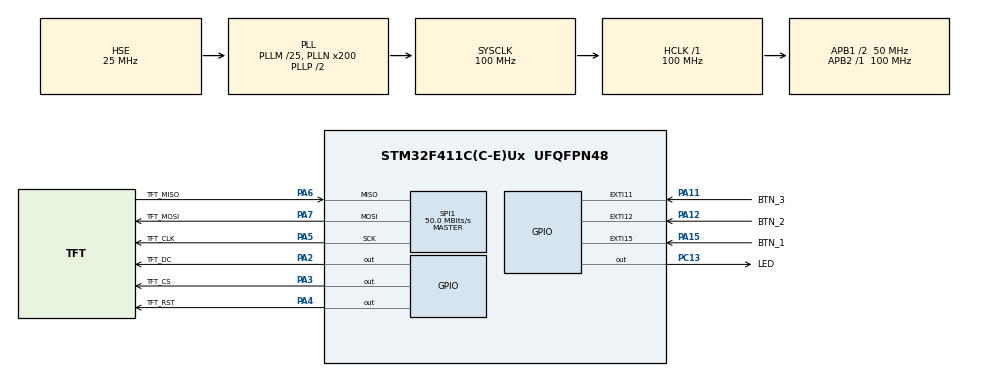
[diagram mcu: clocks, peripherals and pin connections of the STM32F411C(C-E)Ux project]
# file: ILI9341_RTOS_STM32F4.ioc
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Dma.Request0=SPI1_TX
Dma.SPI1_TX.0.Direction=DMA_MEMORY_TO_PERIPH
Dma.SPI1_TX.0.FIFOMode=DMA_FIFOMODE_DISABLE
Dma.SPI1_TX.0.Instance=DMA2_Stream2
Dma.SPI1_TX.0.MemDataAlignment=DMA_MDATAALIGN_BYTE
Dma.SPI1_TX.0.MemInc=DMA_MINC_ENABLE
Dma.SPI1_TX.0.Mode=DMA_NORMAL
Dma.SPI1_TX.0.PeriphDataAlignment=DMA_PDATAALIGN_BYTE
Dma.SPI1_TX.0.PeriphInc=DMA_PINC_DISABLE
Dma.SPI1_TX.0.Priority=DMA_PRIORITY_MEDIUM
FREERTOS.Tasks01=defaultTask,24,128,StartDefaultTask,Default,NULL,Dynamic,NULL,NULL
FREERTOS.configUSE_NEWLIB_REENTRANT=1
Mcu.Family=STM32F4
Mcu.Name=STM32F411C(C-E)Ux
Mcu.Package=UFQFPN48
NVIC.DMA2_Stream2_IRQn=true\:5\:0\:false\:false\:true\:true\:false\:true\:true
NVIC.EXTI15_10_IRQn=true\:5\:0\:false\:false\:true\:true\:true\:true\:true
NVIC.PriorityGroup=NVIC_PRIORITYGROUP_4
NVIC.TIM1_UP_TIM10_IRQn=true\:15\:0\:false\:false\:true\:false\:false\:true\:true
NVIC.TimeBase=TIM1_UP_TIM10_IRQn
NVIC.TimeBaseIP=TIM1
PA11.GPIO_Label=BTN_3
PA11.GPIO_ModeDefaultEXTI=GPIO_MODE_IT_FALLING
PA11.GPIO_PuPd=GPIO_PULLUP
PA11.Signal=GPXTI11
PA12.GPIO_Label=BTN_2
PA12.GPIO_ModeDefaultEXTI=GPIO_MODE_IT_FALLING
PA12.GPIO_PuPd=GPIO_PULLUP
PA12.Signal=GPXTI12
PA15.GPIO_Label=BTN_1
PA15.GPIO_ModeDefaultEXTI=GPIO_MODE_IT_FALLING
PA15.GPIO_PuPd=GPIO_PULLUP
PA15.Signal=GPXTI15
PA2.GPIO_Label=TFT_DC
PA2.GPIO_Speed=GPIO_SPEED_FREQ_VERY_HIGH
PA2.PinState=GPIO_PIN_SET
PA2.Signal=GPIO_Output
PA3.GPIO_Label=TFT_CS
PA3.GPIO_Speed=GPIO_SPEED_FREQ_VERY_HIGH
PA3.PinState=GPIO_PIN_SET
PA3.Signal=GPIO_Output
PA4.GPIO_Label=TFT_RST
PA4.GPIO_Speed=GPIO_SPEED_FREQ_VERY_HIGH
PA4.PinState=GPIO_PIN_SET
PA4.Signal=GPIO_Output
PA5.GPIO_Label=TFT_CLK
PA5.Mode=Full_Duplex_Master
PA5.Signal=SPI1_SCK
PA6.GPIO_Label=TFT_MISO
PA6.Mode=Full_Duplex_Master
PA6.Signal=SPI1_MISO
PA7.GPIO_Label=TFT_MOSI
PA7.Mode=Full_Duplex_Master
PA7.Signal=SPI1_MOSI
PC13-ANTI_TAMP.GPIO_Label=LED
PC13-ANTI_TAMP.GPIO_PuPd=GPIO_NOPULL
PC13-ANTI_TAMP.PinState=GPIO_PIN_SET
PC13-ANTI_TAMP.Signal=GPIO_Output
PH0\ -\ OSC_IN.Mode=HSE-External-Oscillator
PH0\ -\ OSC_IN.Signal=RCC_OSC_IN
PH1\ -\ OSC_OUT.Mode=HSE-External-Oscillator
PH1\ -\ OSC_OUT.Signal=RCC_OSC_OUT
ProjectManager.HeapSize=0x200
ProjectManager.StackSize=0x400
ProjectManager.TargetToolchain=STM32CubeIDE
RCC.48MHZClocksFreq_Value=50000000
RCC.AHBFreq_Value=100000000
RCC.APB1CLKDivider=RCC_HCLK_DIV2
RCC.APB1Freq_Value=50000000
RCC.APB1TimFreq_Value=100000000
RCC.APB2Freq_Value=100000000
RCC.APB2TimFreq_Value=100000000
RCC.CortexFreq_Value=100000000
RCC.HCLKFreq_Value=100000000
RCC.HSE_VALUE=25000000
RCC.HSI_VALUE=16000000
RCC.LSE_VALUE=32768
RCC.PLLM=25
RCC.PLLN=200
RCC.PLLSourceVirtual=RCC_PLLSOURCE_HSE
RCC.SYSCLKFreq_VALUE=100000000
RCC.SYSCLKSource=RCC_SYSCLKSOURCE_PLLCLK
RCC.VCOOutputFreq_Value=200000000
SPI1.CalculateBaudRate=50.0 MBits/s
SPI1.Direction=SPI_DIRECTION_2LINES
SPI1.Mode=SPI_MODE_MASTER
SPI1.VirtualType=VM_MASTER
VP_FREERTOS_VS_CMSIS_V2.Mode=CMSIS_V2
VP_SYS_VS_tim1.Mode=TIM1
board=custom

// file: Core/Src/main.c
/* USER CODE BEGIN Header */
/**
  ******************************************************************************
  * @file           : main.c
  * @brief          : Main program body
  ******************************************************************************
  * @attention
  *
  * Copyright (c) 2022 STMicroelectronics.
  * All rights reserved.
  *
  * This software is licensed under terms that can be found in the LICENSE file
  * in the root directory of this software component.
  * If no LICENSE file comes with this software, it is provided AS-IS.
  *
  ******************************************************************************
  */
/* USER CODE END Header */
#include "main.h"
#include "cmsis_os.h"

/* USER CODE BEGIN Includes */
#include "usercode.h"
/* USER CODE END Includes */

 SPI_HandleTypeDef hspi1;
DMA_HandleTypeDef hdma_spi1_tx;

/* Definitions for defaultTask */
osThreadId_t defaultTaskHandle;
const osThreadAttr_t defaultTask_attributes = {
  .name = "defaultTask",
  .stack_size = 128 * 4,
  .priority = (osPriority_t) osPriorityNormal,
};

void SystemClock_Config(void);
static void MX_GPIO_Init(void);
static void MX_DMA_Init(void);
static void MX_SPI1_Init(void);
void StartDefaultTask(void *argument);

int main(void)
{

  /* MCU Configuration--------------------------------------------------------*/

  /* Reset of all peripherals, Initializes the Flash interface and the Systick. */
  HAL_Init();

  /* Configure the system clock */
  SystemClock_Config();

  /* Initialize all configured peripherals */
  MX_GPIO_Init();
  MX_DMA_Init();
  MX_SPI1_Init();
  /* USER CODE BEGIN 2 */
  inicializar();
  userRTOS();
  /* USER CODE END 2 */

  /* Init scheduler */
  osKernelInitialize();

  /* Create the thread(s) */
  /* creation of defaultTask */
  defaultTaskHandle = osThreadNew(StartDefaultTask, NULL, &defaultTask_attributes);

  /* Start scheduler */
  osKernelStart();

  /* We should never get here as control is now taken by the scheduler */
  /* Infinite loop */
  while (1)
  {

  }
}

void SystemClock_Config(void)
{
  RCC_OscInitTypeDef RCC_OscInitStruct = {0};
  RCC_ClkInitTypeDef RCC_ClkInitStruct = {0};

  /** Configure the main internal regulator output voltage
  */
  __HAL_RCC_PWR_CLK_ENABLE();
  __HAL_PWR_VOLTAGESCALING_CONFIG(PWR_REGULATOR_VOLTAGE_SCALE1);

  /** Initializes the RCC Oscillators according to the specified parameters
  * in the RCC_OscInitTypeDef structure.
  */
  RCC_OscInitStruct.OscillatorType = RCC_OSCILLATORTYPE_HSE;
  RCC_OscInitStruct.HSEState = RCC_HSE_ON;
  RCC_OscInitStruct.PLL.PLLState = RCC_PLL_ON;
  RCC_OscInitStruct.PLL.PLLSource = RCC_PLLSOURCE_HSE;
  RCC_OscInitStruct.PLL.PLLM = 25;
  RCC_OscInitStruct.PLL.PLLN = 200;
  RCC_OscInitStruct.PLL.PLLP = RCC_PLLP_DIV2;
  RCC_OscInitStruct.PLL.PLLQ = 4;
  if (HAL_RCC_OscConfig(&RCC_OscInitStruct) != HAL_OK)
  {
    Error_Handler();
  }

  /** Initializes the CPU, AHB and APB buses clocks
  */
  RCC_ClkInitStruct.ClockType = RCC_CLOCKTYPE_HCLK|RCC_CLOCKTYPE_SYSCLK
                              |RCC_CLOCKTYPE_PCLK1|RCC_CLOCKTYPE_PCLK2;
  RCC_ClkInitStruct.SYSCLKSource = RCC_SYSCLKSOURCE_PLLCLK;
  RCC_ClkInitStruct.AHBCLKDivider = RCC_SYSCLK_DIV1;
  RCC_ClkInitStruct.APB1CLKDivider = RCC_HCLK_DIV2;
  RCC_ClkInitStruct.APB2CLKDivider = RCC_HCLK_DIV1;

  if (HAL_RCC_ClockConfig(&RCC_ClkInitStruct, FLASH_LATENCY_3) != HAL_OK)
  {
    Error_Handler();
  }
}

static void MX_SPI1_Init(void)
{

  /* SPI1 parameter configuration*/
  hspi1.Instance = SPI1;
  hspi1.Init.Mode = SPI_MODE_MASTER;
  hspi1.Init.Direction = SPI_DIRECTION_2LINES;
  hspi1.Init.DataSize = SPI_DATASIZE_8BIT;
  hspi1.Init.CLKPolarity = SPI_POLARITY_LOW;
  hspi1.Init.CLKPhase = SPI_PHASE_1EDGE;
  hspi1.Init.NSS = SPI_NSS_SOFT;
  hspi1.Init.BaudRatePrescaler = SPI_BAUDRATEPRESCALER_2;
  hspi1.Init.FirstBit = SPI_FIRSTBIT_MSB;
  hspi1.Init.TIMode = SPI_TIMODE_DISABLE;
  hspi1.Init.CRCCalculation = SPI_CRCCALCULATION_DISABLE;
  hspi1.Init.CRCPolynomial = 10;
  if (HAL_SPI_Init(&hspi1) != HAL_OK)
  {
    Error_Handler();
  }

}

static void MX_DMA_Init(void)
{

  /* DMA controller clock enable */
  __HAL_RCC_DMA2_CLK_ENABLE();

  /* DMA interrupt init */
  /* DMA2_Stream2_IRQn interrupt configuration */
  HAL_NVIC_SetPriority(DMA2_Stream2_IRQn, 5, 0);
  HAL_NVIC_EnableIRQ(DMA2_Stream2_IRQn);

}

static void MX_GPIO_Init(void)
{
  GPIO_InitTypeDef GPIO_InitStruct = {0};

  /* GPIO Ports Clock Enable */
  __HAL_RCC_GPIOC_CLK_ENABLE();
  __HAL_RCC_GPIOH_CLK_ENABLE();
  __HAL_RCC_GPIOA_CLK_ENABLE();

  /*Configure GPIO pin Output Level */
  HAL_GPIO_WritePin(LED_GPIO_Port, LED_Pin, GPIO_PIN_SET);

  /*Configure GPIO pin Output Level */
  HAL_GPIO_WritePin(GPIOA, TFT_DC_Pin|TFT_CS_Pin|TFT_RST_Pin, GPIO_PIN_SET);

  /*Configure GPIO pin : LED_Pin */
  GPIO_InitStruct.Pin = LED_Pin;
  GPIO_InitStruct.Mode = GPIO_MODE_OUTPUT_PP;
  GPIO_InitStruct.Pull = GPIO_NOPULL;
  GPIO_InitStruct.Speed = GPIO_SPEED_FREQ_LOW;
  HAL_GPIO_Init(LED_GPIO_Port, &GPIO_InitStruct);

  /*Configure GPIO pins : TFT_DC_Pin TFT_CS_Pin TFT_RST_Pin */
  GPIO_InitStruct.Pin = TFT_DC_Pin|TFT_CS_Pin|TFT_RST_Pin;
  GPIO_InitStruct.Mode = GPIO_MODE_OUTPUT_PP;
  GPIO_InitStruct.Pull = GPIO_NOPULL;
  GPIO_InitStruct.Speed = GPIO_SPEED_FREQ_VERY_HIGH;
  HAL_GPIO_Init(GPIOA, &GPIO_InitStruct);

  /*Configure GPIO pins : BTN_3_Pin BTN_2_Pin BTN_1_Pin */
  GPIO_InitStruct.Pin = BTN_3_Pin|BTN_2_Pin|BTN_1_Pin;
  GPIO_InitStruct.Mode = GPIO_MODE_IT_FALLING;
  GPIO_InitStruct.Pull = GPIO_PULLUP;
  HAL_GPIO_Init(GPIOA, &GPIO_InitStruct);

  /* EXTI interrupt init*/
  HAL_NVIC_SetPriority(EXTI15_10_IRQn, 5, 0);
  HAL_NVIC_EnableIRQ(EXTI15_10_IRQn);

}

void StartDefaultTask(void *argument)
{
  for(;;)
  {
    osDelay(1);
  }
}

void HAL_TIM_PeriodElapsedCallback(TIM_HandleTypeDef *htim)
{
  if (htim->Instance == TIM1) {
    HAL_IncTick();
  }
}

void Error_Handler(void)
{
  __disable_irq();
  while (1)
  {
  }
}
